# SWM231 register map
File version: 1.0
CPU: CM0 r1p0, little endian, 2 interrupt priority bits
Registers are 32-bit, read-write, no defined reset value unless marked. A register's access mark holds for its fields unless they carry their own. Offsets are from the block's base; [hi:lo] are bit positions; lines under a group give offsets from that group; {n}, {i} and the like mark numbered series; 'fields as' and 'values as' point back to an identical list.

## TIMRG — Registers group
Base 0x40042400
Same registers: BTIMRG 0x40042C00
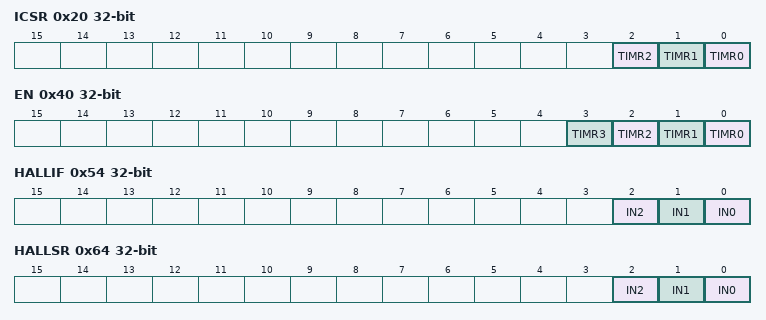
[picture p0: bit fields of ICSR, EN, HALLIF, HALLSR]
0x20 ICSR
  [2] TIMR2, [1] TIMR1, [0] TIMR0
0x40 EN
  [n] TIMR{n} (n=0..3)
0x50 HALLIE
0x54 HALLIF
  [2] IN2, [1] IN1, [0] IN0
0x58 HALLEN
0x5C HALLDR
0x64 HALLSR
  [2] IN2, [1] IN1, [0] IN0

## UART0 — Registers group
Base 0x40040000
Same registers: UART1 0x40040800
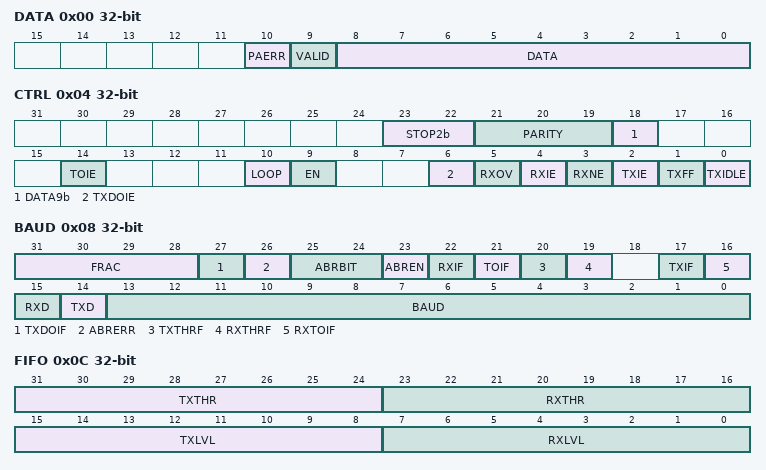
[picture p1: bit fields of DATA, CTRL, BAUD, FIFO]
0x00 DATA
  [10] PAERR, [9] VALID, [8:0] DATA
0x04 CTRL
  [23:22] STOP2b, [21:19] PARITY, [18] DATA9b, [14] TOIE, [10] LOOP, [9] EN, [6] TXDOIE, [5] RXOV, [4] RXIE, [3] RXNE, [2] TXIE, [1] TXFF, [0] TXIDLE
0x08 BAUD
  [31:28] FRAC, [27] TXDOIF, [26] ABRERR, [25:24] ABRBIT, [23] ABREN, [22] RXIF, [21] TOIF, [20] TXTHRF, [19] RXTHRF, [17] TXIF, [16] RXTOIF, [15] RXD, [14] TXD, [13:0] BAUD
0x0C FIFO
  [31:24] TXTHR, [23:16] RXTHR, [15:8] TXLVL, [7:0] RXLVL
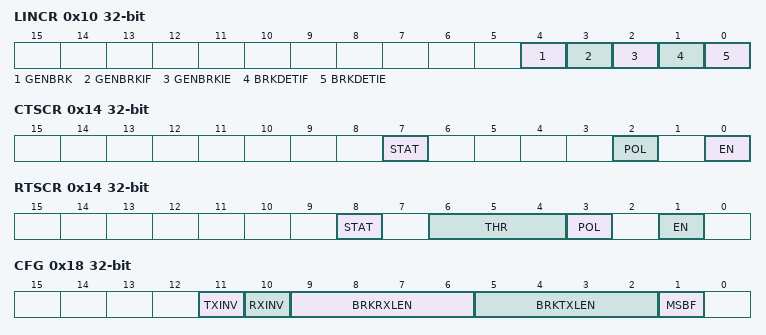
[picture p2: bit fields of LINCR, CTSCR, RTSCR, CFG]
0x10 LINCR
  [4] GENBRK, [3] GENBRKIF, [2] GENBRKIE, [1] BRKDETIF, [0] BRKDETIE
0x14 CTSCR
  [7] STAT, [2] POL, [0] EN
0x14 RTSCR (alternate view of CTSCR)
  [8] STAT, [6:4] THR, [3] POL, [1] EN
0x18 CFG
  [11] TXINV, [10] RXINV, [9:6] BRKRXLEN, [5:2] BRKTXLEN, [1] MSBF
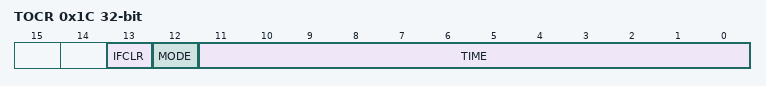
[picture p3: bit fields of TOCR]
0x1C TOCR
  [13] IFCLR, [12] MODE, [11:0] TIME

## SPI0 — Registers group
Base 0x40041000
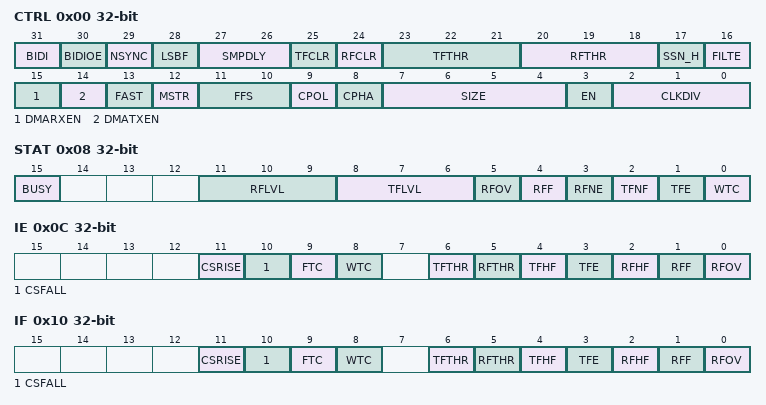
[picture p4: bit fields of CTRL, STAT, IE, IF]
0x00 CTRL
  [31] BIDI, [30] BIDIOE, [29] NSYNC, [28] LSBF, [27:26] SMPDLY, [25] TFCLR, [24] RFCLR, [23:21] TFTHR, [20:18] RFTHR, [17] SSN_H, [16] FILTE, [15] DMARXEN, [14] DMATXEN, [13] FAST, [12] MSTR, [11:10] FFS, [9] CPOL, [8] CPHA, [7:4] SIZE, [3] EN, [2:0] CLKDIV
0x04 DATA
0x08 STAT
  [15] BUSY, [11:9] RFLVL, [8:6] TFLVL, [5] RFOV, [4] RFF, [3] RFNE, [2] TFNF, [1] TFE, [0] WTC
0x0C IE
  [11] CSRISE, [10] CSFALL, [9] FTC, [8] WTC, [6] TFTHR, [5] RFTHR, [4] TFHF, [3] TFE, [2] RFHF, [1] RFF, [0] RFOV
0x10 IF
  fields as IE
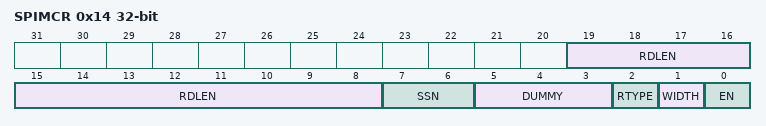
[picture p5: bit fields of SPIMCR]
0x14 SPIMCR
  [19:8] RDLEN, [7:6] SSN, [5:3] DUMMY, [2] RTYPE, [1] WIDTH, [0] EN

## ADC0 — Registers group
Base 0x40043800
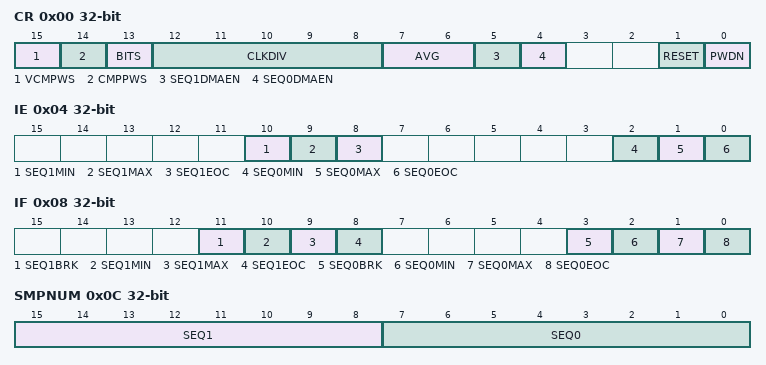
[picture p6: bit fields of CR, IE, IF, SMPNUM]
0x00 CR
  [15] VCMPWS, [14] CMPPWS, [13] BITS, [12:8] CLKDIV, [7:6] AVG, [5] SEQ1DMAEN, [4] SEQ0DMAEN, [1] RESET, [0] PWDN
0x04 IE
  [10] SEQ1MIN, [9] SEQ1MAX, [8] SEQ1EOC, [2] SEQ0MIN, [1] SEQ0MAX, [0] SEQ0EOC
0x08 IF
  [11] SEQ1BRK, [10] SEQ1MIN, [9] SEQ1MAX, [8] SEQ1EOC, [3] SEQ0BRK, [2] SEQ0MIN, [1] SEQ0MAX, [0] SEQ0EOC
0x0C SMPNUM
  [15:8] SEQ1, [7:0] SEQ0
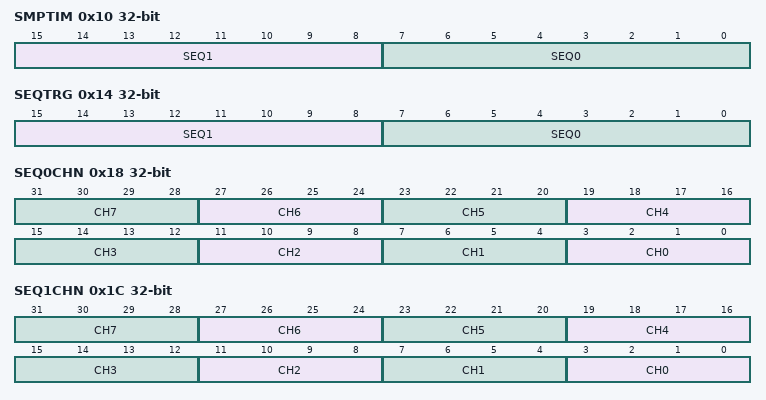
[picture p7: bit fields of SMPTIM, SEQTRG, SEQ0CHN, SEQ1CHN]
0x10 SMPTIM
  [15:8] SEQ1, [7:0] SEQ0
0x14 SEQTRG
  [15:8] SEQ1, [7:0] SEQ0
0x18 SEQ0CHN
  [4n+3:4n] CH{n} (n=0..7)
0x1C SEQ1CHN
  [4n+3:4n] CH{n} (n=0..7)
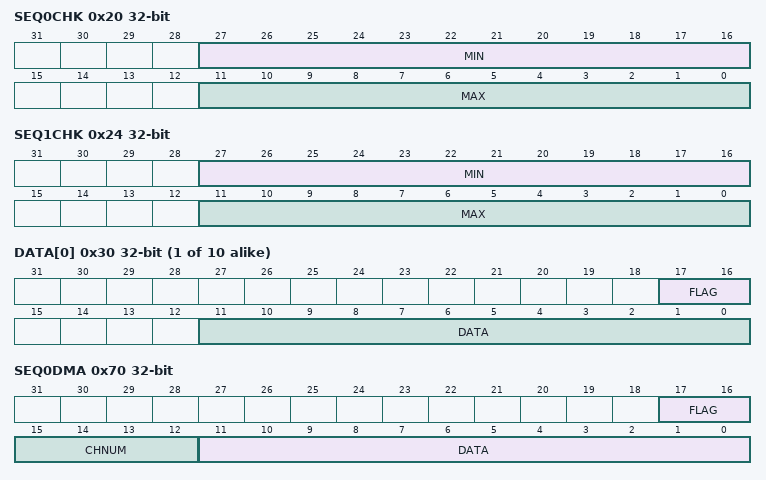
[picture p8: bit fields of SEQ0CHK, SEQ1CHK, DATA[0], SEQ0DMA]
0x20 SEQ0CHK
  [27:16] MIN, [11:0] MAX
0x24 SEQ1CHK
  [27:16] MIN, [11:0] MAX
{0x30+4i} DATA[{i}] (i=0..9)
  [17:16] FLAG, [11:0] DATA
0x70 SEQ0DMA
  [17:16] FLAG, [15:12] CHNUM, [11:0] DATA
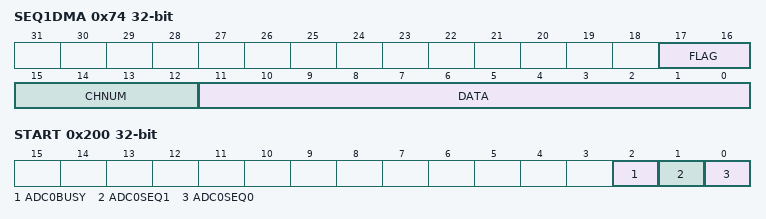
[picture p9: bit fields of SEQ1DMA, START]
0x74 SEQ1DMA
  [17:16] FLAG, [15:12] CHNUM, [11:0] DATA
0x200 START
  [2] ADC0BUSY, [1] ADC0SEQ1, [0] ADC0SEQ0

## PWM0 — Registers group
Base 0x40041800
Same registers: PWM1 0x40041880
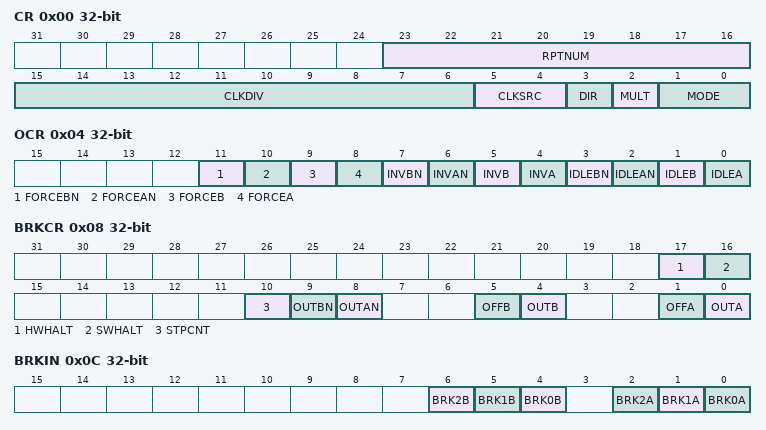
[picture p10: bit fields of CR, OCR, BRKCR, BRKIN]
0x00 CR
  [23:16] RPTNUM, [15:6] CLKDIV, [5:4] CLKSRC, [3] DIR, [2] MULT, [1:0] MODE
0x04 OCR
  [11] FORCEBN, [10] FORCEAN, [9] FORCEB, [8] FORCEA, [7] INVBN, [6] INVAN, [5] INVB, [4] INVA, [3] IDLEBN, [2] IDLEAN, [1] IDLEB, [0] IDLEA
0x08 BRKCR
  [17] HWHALT, [16] SWHALT, [10] STPCNT, [9] OUTBN, [8] OUTAN, [5] OFFB, [4] OUTB, [1] OFFA, [0] OUTA
0x0C BRKIN
  [6] BRK2B, [5] BRK1B, [4] BRK0B, [2] BRK2A, [1] BRK1A, [0] BRK0A
0x20 PERIOD
0x24 CMPA
0x28 CMPB
0x2C DZA
0x30 DZB
0x34 CMPA2
0x38 CMPB2
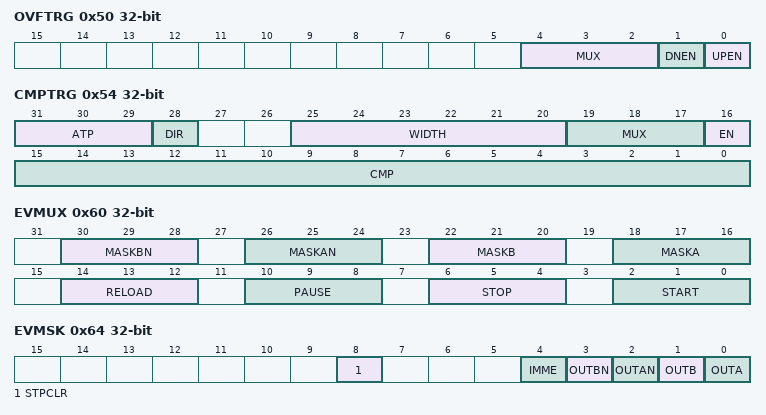
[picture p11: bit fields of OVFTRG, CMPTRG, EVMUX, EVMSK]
0x50 OVFTRG
  [4:2] MUX, [1] DNEN, [0] UPEN
0x54 CMPTRG
  [31:29] ATP, [28] DIR, [25:20] WIDTH, [19:17] MUX, [16] EN, [15:0] CMP
0x58 CMPTRG2
  [2:0] INTV
0x60 EVMUX
  [30:28] MASKBN, [26:24] MASKAN, [22:20] MASKB, [18:16] MASKA, [14:12] RELOAD, [10:8] PAUSE, [6:4] STOP, [2:0] START
0x64 EVMSK
  [8] STPCLR, [4] IMME, [3] OUTBN, [2] OUTAN, [1] OUTB, [0] OUTA
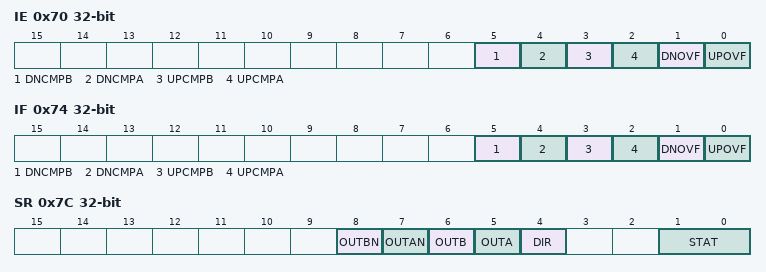
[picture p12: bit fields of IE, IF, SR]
0x70 IE
  [5] DNCMPB, [4] DNCMPA, [3] UPCMPB, [2] UPCMPA, [1] DNOVF, [0] UPOVF
0x74 IF
  [5] DNCMPB, [4] DNCMPA, [3] UPCMPB, [2] UPCMPA, [1] DNOVF, [0] UPOVF
0x78 VALUE
0x7C SR
  [8] OUTBN, [7] OUTAN, [6] OUTB, [5] OUTA, [4] DIR, [1:0] STAT

## PWMG — Registers group
Base 0x40041C00
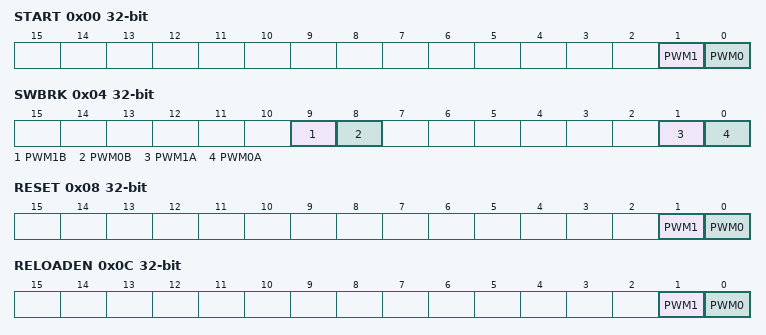
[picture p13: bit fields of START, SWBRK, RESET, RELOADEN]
0x00 START
  [1] PWM1, [0] PWM0
0x04 SWBRK
  [9] PWM1B, [8] PWM0B, [1] PWM1A, [0] PWM0A
0x08 RESET
  [1] PWM1, [0] PWM0
0x0C RELOADEN
  [1] PWM1, [0] PWM0
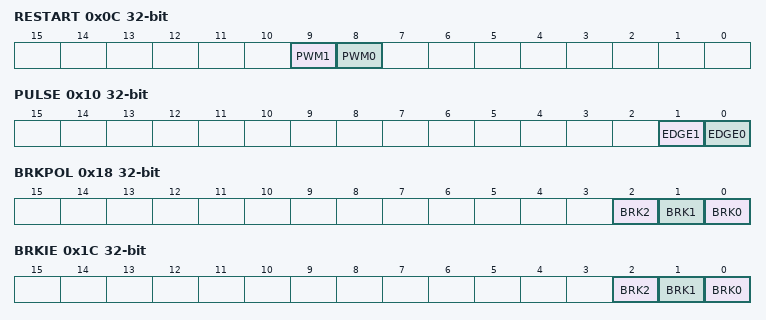
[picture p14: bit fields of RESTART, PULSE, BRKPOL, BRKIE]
0x0C RESTART (alternate view of RELOADEN)
  [9] PWM1, [8] PWM0
0x10 PULSE
  [1] EDGE1, [0] EDGE0
0x14 FILTER
0x18 BRKPOL
  [2] BRK2, [1] BRK1, [0] BRK0
0x1C BRKIE
  [2] BRK2, [1] BRK1, [0] BRK0
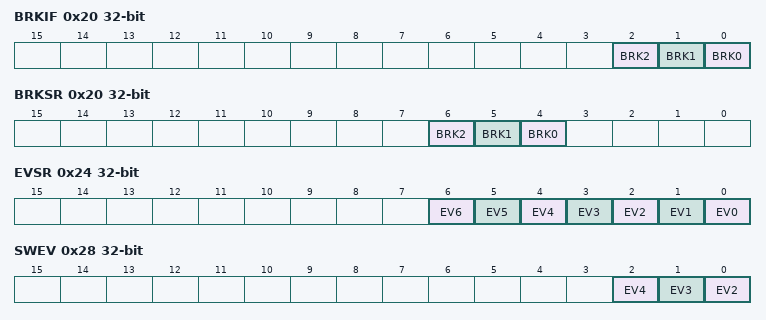
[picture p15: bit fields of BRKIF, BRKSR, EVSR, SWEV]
0x20 BRKIF
  [2] BRK2, [1] BRK1, [0] BRK0
0x20 BRKSR (alternate view of BRKIF)
  [6] BRK2, [5] BRK1, [4] BRK0
0x24 EVSR
  [n] EV{n} (n=0..6)
0x28 SWEV
  [2] EV4, [1] EV3, [0] EV2

## DIV — Registers group
Base 0x40001800
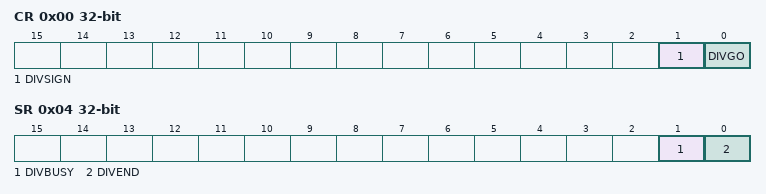
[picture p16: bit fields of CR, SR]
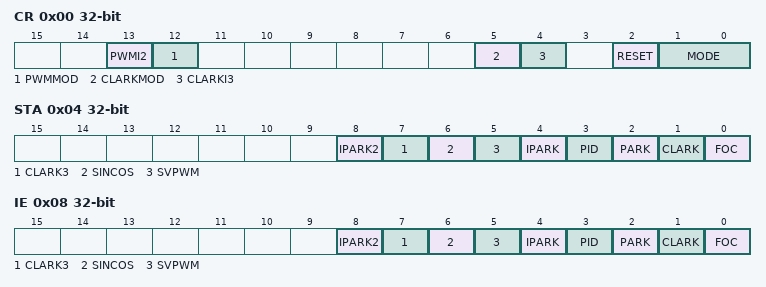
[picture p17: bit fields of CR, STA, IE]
0x00 CR
  [1] DIVSIGN, [0] DIVGO
0x04 SR
  [1] DIVBUSY, [0] DIVEND
0x08 IE
0x10 DIVIDEND
0x14 DIVISOR
0x18 QUO
0x1C REMAIN

## FOC — Registers group
Base 0x40043000
0x00 CR
  [13] PWMI2, [12] PWMMOD, [5] CLARKMOD, [4] CLARKI3, [2] RESET, [1:0] MODE
0x04 STA
  [8] IPARK2, [7] CLARK3, [6] SINCOS, [5] SVPWM, [4] IPARK, [3] PID, [2] PARK, [1] CLARK, [0] FOC
0x08 IE
  fields as STA
0x0C SR
  [20] SVPWMOF, [19] IPARKOF, [18] PIDOF, [17] PARKOF, [16] CLARKOF, [9] IPARK2, [8] CLARK3, [7] SINCOS, [6] SVPWM, [5] IPARK, [4] PID, [3] PARK, [2] CLARK, [1] FOC, [0] BUSY
0x14 CLARKIA
0x18 CLARKIB
0x1C CLARKIC
0x20 CLARKOA ro
0x24 CLARKOB ro
0x28 PARKIA
0x2C PARKIB
0x30 PARKSIN
0x34 PARKCOS
0x38 PARKOD ro
0x3C PARKOQ ro
0x44 PIDID
0x48 PIDIQ
0x4C PIDREFD
0x50 PIDREFQ
0x54 PIDMAXD
0x58 PIDMAXQ
0x5C PIDMIND
0x60 PIDMINQ
0x64 PIDKPD
0x68 PIDKPQ
0x6C PIDKID
0x70 PIDKIQ
0x74 PIDLED
0x78 PIDLEQ
0x7C PIDLOD
0x80 PIDLOQ
0x84 PIDOD ro
0x88 PIDOQ ro
0x8C IPARKID
0x90 IPARKIQ
0x94 IPARKSIN
0x98 IPARKCOS
0x9C IPARKOA ro
0xA0 IPARKOB ro
0xA4 PWMIBV
0xA8 PWMIA
0xAC PWMIB
0xB0 PWMMIN
{0xB0+4i} PWMDLY{i} (i=1..3)
0xC0 PWMTIM
0xC4 PWMDZ
0xC8 PWMSP1 ro
0xCC PWMSP2 ro
0xD0 PWMTDA ro
0xD4 PWMTDAN ro
0xD8 PWMTDB ro
0xDC PWMTDBN ro
0xE0 PWMTDC ro
0xE4 PWMTDCN ro
0xE8 PWMSECT ro
0xEC PWMOVA ro
0xF0 PWMOVB ro
0xF4 IANGLE
0xF8 OSIN ro
0xFC OCOS ro

## DMA — Registers group
Base 0x40000800
0x00 IF
  [3] ERR0, [2] HALF0, [1] DONE0, [0] GLB0
0x04 IFC
  [3] ERR0, [2] HALF0, [1] DONE0, [0] GLB0
0x10 CH0 group — register cluster
  0x00 MUX
    [11] EXTHSEN, [10:8] EXTHSSIG, [7] MWRHSEN, [5:4] MWRHSSIG, [3] MRDHSEN, [1:0] MRDHSSIG
  0x04 CR
    [16] MEM2MEM, [15:12] PL, [11:10] MSIZ, [9:8] PSIZ, [7] MINC, [6] PINC, [5] CIRC, [4] DIR, [3] ERRIE, [2] HALFIE, [1] DONEIE, [0] EN
  0x08 NDT
    [26:24] HALF, [23:0] LEN
  0x0C PAR
  0x10 MAR

## FMC — Registers group
Base 0x40044000
0x00 DATA
0x04 ADDR
0x08 ERASE
  [31:24] REQ, [16:0] ADDR
0x10 CFG0
  [0] WREN
{0x10+4i} CFG{i} (i=1..4)
0x24 STAT
  [31] IDLE, [30] INITDONE, [7] READONLY, [4] FIFOFULL, [3] FIFOEMPTY, [2] READBUSY, [1] PROGBUSY, [0] ERASEBUSY
0x28 REMAP
  [4:1] OFFSET, [0] ON

## WDT — Registers group
Base 0x40045800
0x00 RSTVAL
0x04 INTVAL
0x08 CR
  [11:8] CLKDIV, [3] WINEN, [2] INTEN, [1] RSTEN, [0] EN
0x0C IF
0x10 FEED
